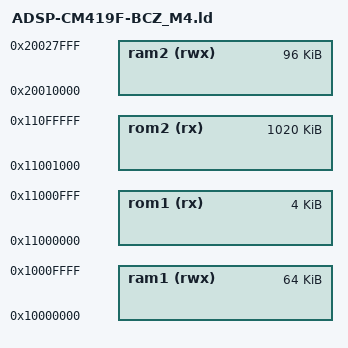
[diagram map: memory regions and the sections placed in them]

MEMORY
{
  rom1 (rx) : ORIGIN = 0x11000000, LENGTH = 0x00001000
  rom2 (rx) : ORIGIN = 0x11001000, LENGTH = 0x000FF000
  ram1 (rwx) : ORIGIN = 0x10000000, LENGTH = 0x00010000
  ram2 (rwx) : ORIGIN = 0x20010000, LENGTH = 0x00018000
}

